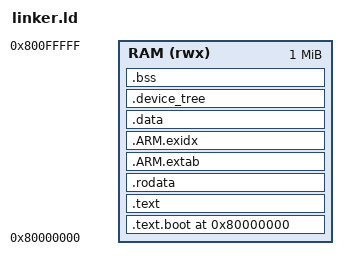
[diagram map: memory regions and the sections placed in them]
/* linker.ld
 *
 * ARM32 linker script for the XNU bootloader
 */

ENTRY(_start)

MEMORY
{
    RAM (rwx) : ORIGIN = 0x80000000, LENGTH = 1M
}

STACK_SIZE = 64K;

SECTIONS
{
    . = ORIGIN(RAM);

    __image_start = .;

    /* ------------------------------------------------------------------ */
    /* Boot entry (must be first)                                         */
    /* ------------------------------------------------------------------ */

    .text.boot ALIGN(16) :
    {
        KEEP(*(.text.boot))
        KEEP(*(.text.boot.*))
    } > RAM

    /* ------------------------------------------------------------------ */
    /* Code                                                                */
    /* ------------------------------------------------------------------ */

    .text ALIGN(16) :
    {
        *(.text)
        *(.text.*)
    } > RAM

    /* ------------------------------------------------------------------ */
    /* Read-only data                                                      */
    /* ------------------------------------------------------------------ */

    .rodata ALIGN(16) :
    {
        *(.rodata)
        *(.rodata.*)
        *(.gnu.linkonce.r*)
    } > RAM

    /* ------------------------------------------------------------------ */
    /* Exception tables                                                    */
    /* ------------------------------------------------------------------ */

    .ARM.extab ALIGN(8) :
    {
        *(.ARM.extab*)
    } > RAM

    .ARM.exidx ALIGN(8) :
    {
        __exidx_start = .;
        *(.ARM.exidx*)
        __exidx_end = .;
    } > RAM

    /* ------------------------------------------------------------------ */
    /* Initialized data                                                    */
    /* ------------------------------------------------------------------ */

    .data ALIGN(16) :
    {
        __data_start = .;
        *(.data)
        *(.data.*)
        __data_end = .;
    } > RAM

    /* ------------------------------------------------------------------ */
    /* Embedded Apple DeviceTree                                           */
    /* ------------------------------------------------------------------ */

    .device_tree ALIGN(4096) :
    {
        _device_tree_start = .;
        KEEP(*(.device_tree))
        KEEP(*(.dtb))
        KEEP(*(.apple_dtb))
        _device_tree_end = .;
    } > RAM

    /* ------------------------------------------------------------------ */
    /* BSS                                                                 */
    /* ------------------------------------------------------------------ */

    .bss ALIGN(16) :
    {
        __bss_start = .;
        *(.bss)
        *(.bss.*)
        *(COMMON)
        __bss_end = .;
    } > RAM

    /* ------------------------------------------------------------------ */
    /* Stack                                                               */
    /* ------------------------------------------------------------------ */

    . = ALIGN(16);

    __stack_bottom = .;
    . += STACK_SIZE;
    __stack_top = .;

    __image_end = .;
}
